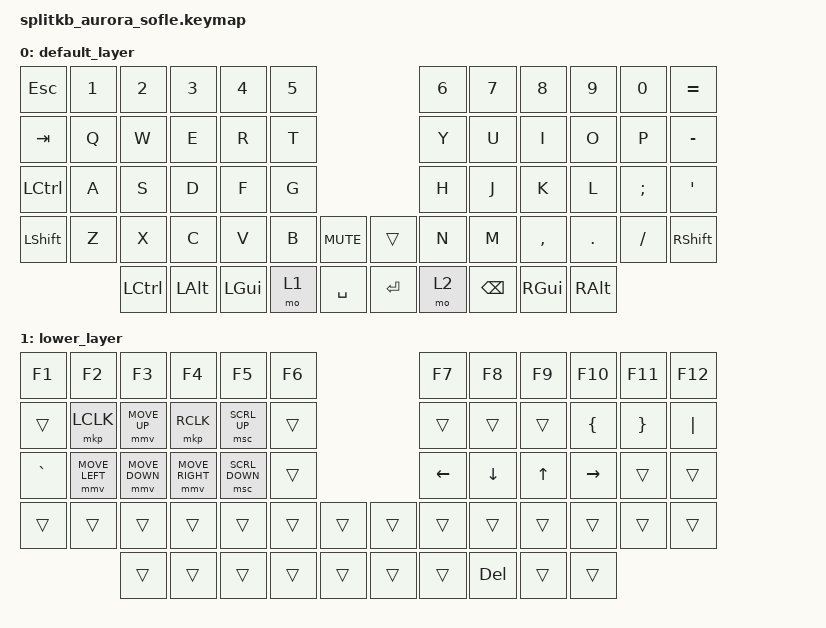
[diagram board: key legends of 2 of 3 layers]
/*
 * Copyright (c) 2023 The ZMK Contributors
 *
 * SPDX-License-Identifier: MIT
 */

#include <behaviors.dtsi>
#include <dt-bindings/zmk/keys.h>
#include <dt-bindings/zmk/bt.h>
#include <dt-bindings/zmk/ext_power.h>

#define ZMK_POINTING_DEFAULT_MOVE_VAL 1000  // default: 600
#define ZMK_POINTING_DEFAULT_SCRL_VAL 15    // default: 10

#include <dt-bindings/zmk/pointing.h>

/* Uncomment this block if using RGB
&led_strip {
    chain-length = <6>;
    // chain-length = <35>; // Uncomment if using both per-key and underglow LEDs
    // chain-length = <29>; // Uncomment if using only per-key LEDs.
};
 */

/ {
    keymap {
        compatible = "zmk,keymap";

        default_layer {
// ------------------------------------------------------------------------------------------------------------
// |  ESC  |  1  |  2  |  3   |  4   |  5   |                   |  6   |  7    |  8    |  9   |   0   |   +   |
// |  TAB  |  Q  |  W  |  E   |  R   |  T   |                   |  Y   |  U    |  I    |  O   |   P   |   -   |
// |  CTRL |  A  |  S  |  D   |  F   |  G   |                   |  H   |  J    |  K    |  L   |   ;   |   '   |
// | SHIFT |  Z  |  X  |  C   |  V   |  B   |  MUTE  |  |       |  N   |  M    |  ,    |  .   |   /   | SHIFT |
//               |CTRL | ALT  | GUI  | LOWER|  SPACE |  | ENTER | RAISE| BSPC  | GUI   | RALT |
            bindings = <
&kp ESC   &kp N1 &kp N2    &kp N3   &kp N4   &kp N5                     &kp N6 &kp N7   &kp N8    &kp N9   &kp N0   &kp EQUAL
&kp TAB   &kp Q  &kp W     &kp E    &kp R    &kp T                      &kp Y  &kp U    &kp I     &kp O    &kp P    &kp MINUS
&kp LCTRL &kp A  &kp S     &kp D    &kp F    &kp G                      &kp H  &kp J    &kp K     &kp L    &kp SEMI &kp SQT
&kp LSHFT &kp Z  &kp X     &kp C    &kp V    &kp B  &kp C_MUTE &trans   &kp N  &kp M    &kp COMMA &kp DOT  &kp FSLH &kp RSHFT
                 &kp LCTRL &kp LALT &kp LGUI &mo 1  &kp SPACE  &kp RET  &mo 2  &kp BSPC &kp RGUI  &kp RALT
            >;

            sensor-bindings = <&inc_dec_kp C_VOL_UP C_VOL_DN &inc_dec_kp PG_UP PG_DN>;
        };

        lower_layer {
// ------------------------------------------------------------------------------------------------------------
// |  F1   |  F2 |  F3 |  F4  |  F5  |  F6  |                   |  F7  |  F8   |  F9   |  F10 |  F11  |  F12  |
// |       |     |     |      |      |      |                   |      |       |       |  {   |   }   |  "|"  |
// |   ~   |     |     |      |      |      |                   |  <-  |  v    |   ^   |  ->  |       |       |
// |       |     |     |      |      |      |        |  |       |      |       |       |      |       |       |
//               |     |      |      |      |        |  |       |      | DEL   |       |      |
            bindings = <
&kp F1     &kp F2           &kp F3            &kp F4          &kp F5          &kp F6                       &kp F7      &kp F8    &kp F9    &kp F10   &kp F11   &kp F12
&trans     &mkp LCLK        &mmv MOVE_UP      &mkp RCLK       &msc SCRL_UP    &trans                       &trans      &trans    &trans    &kp LBRC  &kp RBRC  &kp PIPE
&kp GRAVE  &mmv MOVE_LEFT   &mmv MOVE_DOWN    &mmv MOVE_RIGHT &msc SCRL_DOWN  &trans                       &kp LEFT    &kp DOWN  &kp UP    &kp RIGHT &trans    &trans
&trans     &trans           &trans            &trans          &trans          &trans    &trans   &trans    &trans      &trans    &trans    &trans    &trans    &trans
                            &trans            &trans          &trans          &trans    &trans   &trans    &trans      &kp DEL   &trans    &trans
            >;

            sensor-bindings = <&inc_dec_kp C_VOL_UP C_VOL_DN &inc_dec_kp PG_UP PG_DN>;
        };

        raise_layer {
// ------------------------------------------------------------------------------------------------------------
// |  F1   |  F2 |  F3 |  F4  |  F5  |  F6  |                   |  F7  |  F8   |  F9   |  F10 |  F11  |  F12  |
// |       |     |     |      |      |      |                   |      |       |       |   [  |  ]    |   \   |
// |   `   |     |     |      |      |      |                   |  <-  |   v   |   ^   |  ->  |       |       |
// |       |     |     |      |      |      |        |  |       |      |       |       |      |       |       |
//               |     |      |      |      |        |  |       |      |       |       |      |
            bindings = <
&kp F1    &kp F2         &kp F3         &kp F4           &kp F5          &kp F6                   &kp F7    &kp F8      &kp F9    &kp F10   &kp F11   &kp F12
&trans    &mkp LCLK      &mmv MOVE_UP   &mkp RCLK        &msc SCRL_UP    &trans                   &trans    &trans      &trans    &kp LBKT  &kp RBKT  &kp BSLH
&kp TILDE &mmv MOVE_LEFT &mmv MOVE_DOWN &mmv MOVE_RIGHT  &msc SCRL_DOWN  &trans                   &kp LEFT  &kp DOWN    &kp UP    &kp RIGHT &trans    &trans
&trans    &trans         &trans         &trans           &trans          &trans    &trans &trans  &trans    &trans      &trans    &trans    &trans    &trans
                         &trans         &trans           &trans          &trans    &trans &trans  &trans    &trans      &trans    &trans    &trans
            >;

            sensor-bindings = <&inc_dec_kp C_VOL_UP C_VOL_DN &inc_dec_kp PG_UP PG_DN>;
        };
    };
};
